# ATA5833 device description
Architecture: AVR8; Family: megaAVR
Registers are 8-bit, access not given, no defined reset value unless marked. A register's access mark holds for its fields unless they carry their own. Offsets are from the block's base; [hi:lo] are bit positions; {n}, {i} and the like mark numbered series.

## FE
Instances: FE 0x00
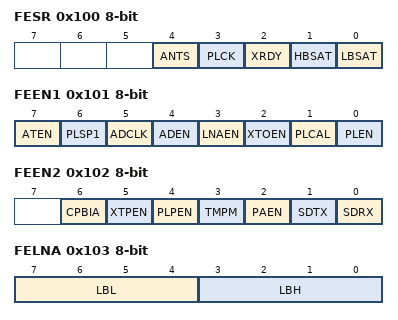
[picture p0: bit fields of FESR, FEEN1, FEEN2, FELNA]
0x100 FESR — Front-End Status Register
  [4] ANTS — Antenna saturated
  [3] PLCK — PLL locked
  [2] XRDY — XTO ready
  [1] HBSAT — LNA High band saturated
  [0] LBSAT — LNA Low band saturated
0x101 FEEN1 — Front-End Enable Register 1
  [7] ATEN — Antenna Tuning Enable
  [6] PLSP1 — PLL Speedup 1
  [5] ADCLK — ADC Clock enable
  [4] ADEN — Analog Digital Converter enable
  [3] LNAEN — Low Noise Amplifier enable
  [2] XTOEN — Cristal Oscillator enable
  [1] PLCAL — PLL calibration mode
  [0] PLEN — PLL enable
0x102 FEEN2 — Front-End Enable Register 2
  [6] CPBIA — Cap Array Bias
  [5] XTPEN — XTO VPump enable
  [4] PLPEN — PLL Post En IQ divider
  [3] TMPM — Temperature measurement
  [2] PAEN — Power Amplifier enable
  [1] SDTX — Single Pole Double Throw (SPDT) Switch TX
  [0] SDRX — Single Pole Double Throw (SPDT) Switch RX
0x103 FELNA — Front-End LNA Bias Register
  [7:4] LBL — LNA Bias Low band
  [3:0] LBH — LNA Bias High band
0x104 FEAT — Front-End Antenna Tuning
  [3:0] ANTN — Antenna Tuning
0x105 FEPAC — Front-End Power Amplifier Control Register Pout/dBm LowBand HighBand
0x106 FEVCT — Front-End VCO Tuning Register
  [3:0] FEVCT
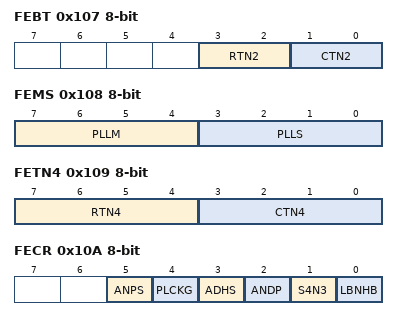
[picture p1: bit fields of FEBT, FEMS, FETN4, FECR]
0x107 FEBT — Front-End RC Tuning Register
  [3:2] RTN2 — Resistor Tuning
  [1:0] CTN2 — Capacitor Tuning
0x108 FEMS — Front-End Main and Swallow Control Register
  [7:4] PLLM — PLL Mode
  [3:0] PLLS — PLL Swallow
0x109 FETN4 — Front-End RC Tuning 4bit Register
  [7:4] RTN4 — 4 bit Resistor Tuning
  [3:0] CTN4 — 4 bit Capacitor Tuning
0x10A FECR — Front-End Control Register
  [5] ANPS — ASK Not DPSK Switch
  [4] PLCKG — PLL Lock Detect Gate
  [3] ADHS — ADC High Sample Rate
  [2] ANDP — Antenna Damping
  [1] S4N3 — Select 433 Not 315MHz Band
  [0] LBNHB — Select Low-Band Not High-Band
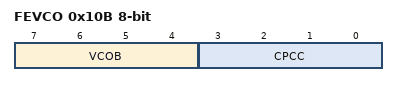
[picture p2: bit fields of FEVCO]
0x10B FEVCO — Front-End VCO and PLL control
  [7:4] VCOB — VCO Bias
  [3:0] CPCC — Charge pump current control
0x10C FEALR — Front-End Antenna Level Detector Range
  [1:0] RNGE — Range of the ANT_TUNE level detector
    0=0_3_DBM; 1=4_7_DBM; 2=8_14_DBM; 3=SECURE_MEASUREMENT
0x10D FEANT — Front-End ANTenna
  [3:0] LVLC — antenna signal LeVeL
0x10E FEBIA — Front-End IF Amplifier BIAS
  [7] IFAEN — IF Amplifier Enable
Value list FE_POWER_AMPLIFIER_CONTROL: 0=_11_80_12_90; 1=_11_30_12_33; 2=_10_70_11_76; 3=_10_20_11_10; 4=_9_70_10_60; 5=_9_20_10_00; 6=_8_60_9_50; 7=_8_00_9_00; 8=_7_50_8_50; 9=_7_00_7_90; 10=_6_40_7_30; 11=_5_90_6_80; 12=_5_30_6_30; 13=_4_77_5_70; 14=_4_17_5_20; 15=_3_67_4_60; 16=_3_12_4_07; 17=_2_56_3_47; 18=_2_10_2_97; 19=_1_58_2_42; 20=_1_08_1_86; 21=_0_50_1_40; 22=_0_00_0_88; 23=_0_41_0_38; 24=_1_00_0_20; 25=_1_42_0_70; 26=_1_83_1_11; 27=_2_42_1_70; 28=_2_88_2_12; 29=_3_38_2_53; 30=_3_81_3_12; 31=_4_31_3_58; 32=_4_72_4_08; 33=_5_09_4_51; 34=_5_57_5_01; 35=_6_00_5_42; 36=_6_41_5_79; 37=_6_77_6_27; 38=_7_19_6_70; 39=_7_55_7_11; 40=_7_98_7_47; 41=_8_40_7_89; 42=_8_79_8_25; 43=_9_11_8_68; 44=_9_46_9_10; 45=_9_82_9_49; 46=_10_18_9_81; 47=_10_60_10_16; 48=_10_89_10_52; 49=_11_30_10_88; 50=_11_62_11_30; 51=_12_06_11_59; 52=_12_39_12_00; 53=_12_82_12_32; 54=_13_22_12_76; 55=_13_58_13_09; 56=_13_95_13_52; 57=_14_22_13_92; 58=_14_41_14_28; 59=_14_49_14_65; {v}=_14_60_14_65 (v=60..63)

## FREQS
Instances: FREQS 0x00
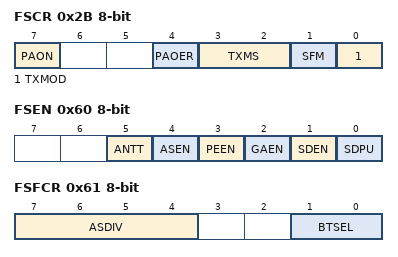
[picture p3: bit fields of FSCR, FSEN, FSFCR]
0x2B FSCR — Frequency Synthesizer Control Register
  [7] PAON — Power Amplifier Output is On
  [4] PAOER — Power Amplifier Output Enable Register
  [3:2] TXMS — Tx Modulation Source
    0=TXMOD_REGISTER; 1=TMDI_INPUT; 2=TX_MODULATOR_SERIAL_OUT
  [1] SFM — Select FSK Modulation
  [0] TXMOD — Tx Modulation
0x60 FSEN — Frequency Synthesizer Enable register
  [5] ANTT — Antenna Tuning Active
  [4] ASEN — ASK Shaping Enable
  [3] PEEN — Pre-emphasis Filtering Enable
  [2] GAEN — Gauss Filtering Enable
  [1] SDEN — Sigma-delta Modulator Enable
  [0] SDPU — Sigma-delta Modulator Power Up
0x61 FSFCR — Frequency Synthesizer Filter Control Register
  [7:4] ASDIV — ASK Shaping Divider
  [1:0] BTSEL — Gauss Filter BT Selection
0x62 GACDIV 16-bit bits used 12:0 — Gauss Clock Divider
0x64 FFREQ1L — Fractional Frequency 1 Setting, Low Byte
0x65 FFREQ1M — Fractional Frequency 1 Setting, Middle Byte
0x66 FFREQ1H bits used 1:0 — Fractional Frequency 1 Setting, High Byte
0x67 FFREQ2L — Fractional Frequency 2 Setting, Low Byte
0x68 FFREQ2M — Fractional Frequency 2 Setting, Middle Byte
0x69 FFREQ2H bits used 1:0 — Fractional Frequency 2 Setting, High Byte
